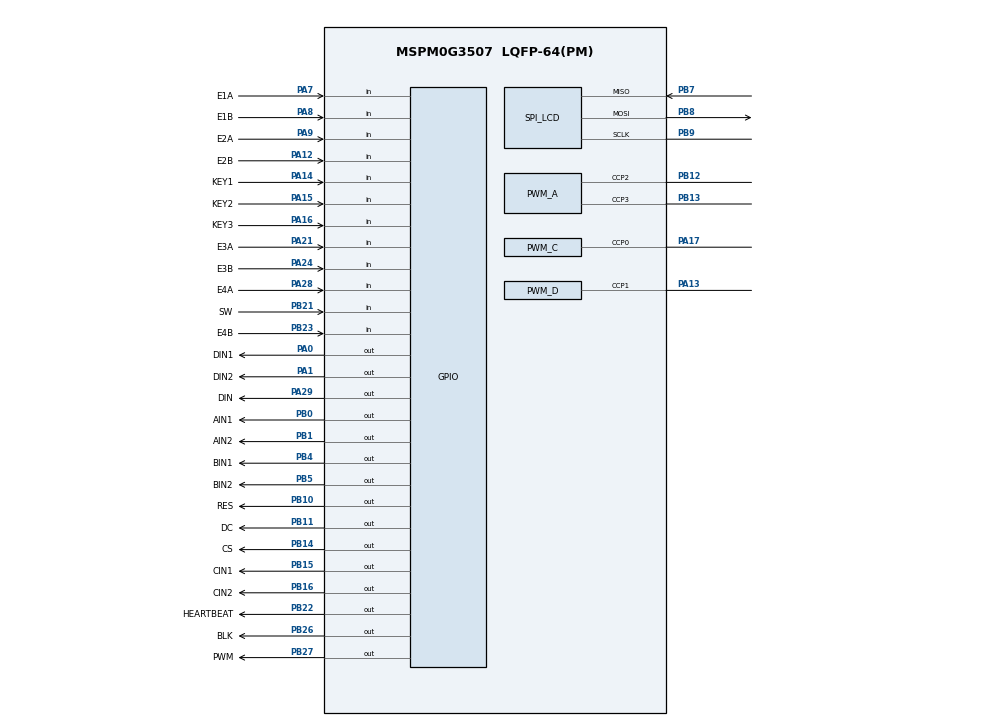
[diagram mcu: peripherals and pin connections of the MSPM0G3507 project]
/**
 * @cliArgs --device "MSPM0G3507" --package "LQFP-64(PM)" --product "mspm0_sdk@2.11.00.07"
 */
const GPIO = scripting.addModule("/ti/driverlib/GPIO", {}, false);
const LCD_RES = GPIO.addInstance();
const LCD_DC = GPIO.addInstance();
const LCD_CS = GPIO.addInstance();
const LCD_BLK = GPIO.addInstance();
const KEY_INPUT = GPIO.addInstance();
const KEY1_INPUT = GPIO.addInstance();
const KEY2_INPUT = GPIO.addInstance();
const KEY3_INPUT = GPIO.addInstance();
const DIR_A = GPIO.addInstance();
const DIR_B = GPIO.addInstance();
const DIR_C = GPIO.addInstance();
const DIR_D = GPIO.addInstance();
const ENCODER_A = GPIO.addInstance();
const ENCODER_B = GPIO.addInstance();
const ENCODER_C = GPIO.addInstance();
const ENCODER_D_A = GPIO.addInstance();
const ENCODER_D_B = GPIO.addInstance();
const GPIO_HEARTBEAT = GPIO.addInstance();
const WS2812 = GPIO.addInstance();
const BUZZER = GPIO.addInstance();
const PWM = scripting.addModule("/ti/driverlib/PWM", {}, false);
const PWM_A = PWM.addInstance();
const PWM_D = PWM.addInstance();
const SPI = scripting.addModule("/ti/driverlib/SPI", {}, false);
const SPI_LCD = SPI.addInstance();
const SYSCTL = scripting.addModule("/ti/driverlib/SYSCTL");
const Board = scripting.addModule("/ti/driverlib/Board", {}, false);

LCD_RES.$name = "LCD_RES";
LCD_RES.port = "PORTB";
LCD_RES.associatedPins[0].$name = "RES";
LCD_RES.associatedPins[0].assignedPort = "PORTB";
LCD_RES.associatedPins[0].assignedPin = "10";
LCD_RES.associatedPins[0].direction = "OUTPUT";
LCD_RES.associatedPins[0].initialValue = "SET";
LCD_RES.associatedPins[0].pin.$assign = "PB10";

LCD_DC.$name = "LCD_DC";
LCD_DC.port = "PORTB";
LCD_DC.associatedPins[0].$name = "DC";
LCD_DC.associatedPins[0].assignedPort = "PORTB";
LCD_DC.associatedPins[0].assignedPin = "11";
LCD_DC.associatedPins[0].direction = "OUTPUT";
LCD_DC.associatedPins[0].initialValue = "SET";
LCD_DC.associatedPins[0].pin.$assign = "PB11";

LCD_CS.$name = "LCD_CS";
LCD_CS.port = "PORTB";
LCD_CS.associatedPins[0].$name = "CS";
LCD_CS.associatedPins[0].assignedPort = "PORTB";
LCD_CS.associatedPins[0].assignedPin = "14";
LCD_CS.associatedPins[0].direction = "OUTPUT";
LCD_CS.associatedPins[0].initialValue = "SET";
LCD_CS.associatedPins[0].pin.$assign = "PB14";

LCD_BLK.$name = "LCD_BLK";
LCD_BLK.port = "PORTB";
LCD_BLK.associatedPins[0].$name = "BLK";
LCD_BLK.associatedPins[0].assignedPort = "PORTB";
LCD_BLK.associatedPins[0].assignedPin = "26";
LCD_BLK.associatedPins[0].direction = "OUTPUT";
LCD_BLK.associatedPins[0].initialValue = "CLEARED";
LCD_BLK.associatedPins[0].pin.$assign = "PB26";

KEY_INPUT.$name = "KEY_INPUT";
KEY_INPUT.port = "PORTB";
KEY_INPUT.associatedPins[0].$name = "SW";
KEY_INPUT.associatedPins[0].assignedPort = "PORTB";
KEY_INPUT.associatedPins[0].assignedPin = "21";
KEY_INPUT.associatedPins[0].direction = "INPUT";
KEY_INPUT.associatedPins[0].internalResistor = "PULL_UP";
KEY_INPUT.associatedPins[0].pin.$assign = "PB21";

KEY1_INPUT.$name = "KEY1_INPUT";
KEY1_INPUT.port = "PORTA";
KEY1_INPUT.associatedPins[0].$name = "KEY1";
KEY1_INPUT.associatedPins[0].assignedPort = "PORTA";
KEY1_INPUT.associatedPins[0].assignedPin = "14";
KEY1_INPUT.associatedPins[0].direction = "INPUT";
KEY1_INPUT.associatedPins[0].internalResistor = "PULL_UP";
KEY1_INPUT.associatedPins[0].pin.$assign = "PA14";

KEY2_INPUT.$name = "KEY2_INPUT";
KEY2_INPUT.port = "PORTA";
KEY2_INPUT.associatedPins[0].$name = "KEY2";
KEY2_INPUT.associatedPins[0].assignedPort = "PORTA";
KEY2_INPUT.associatedPins[0].assignedPin = "15";
KEY2_INPUT.associatedPins[0].direction = "INPUT";
KEY2_INPUT.associatedPins[0].internalResistor = "PULL_UP";
KEY2_INPUT.associatedPins[0].pin.$assign = "PA15";

KEY3_INPUT.$name = "KEY3_INPUT";
KEY3_INPUT.port = "PORTA";
KEY3_INPUT.associatedPins[0].$name = "KEY3";
KEY3_INPUT.associatedPins[0].assignedPort = "PORTA";
KEY3_INPUT.associatedPins[0].assignedPin = "16";
KEY3_INPUT.associatedPins[0].direction = "INPUT";
KEY3_INPUT.associatedPins[0].internalResistor = "PULL_UP";
KEY3_INPUT.associatedPins[0].pin.$assign = "PA16";

DIR_A.$name = "DIR_A";
DIR_A.port = "PORTB";
DIR_A.associatedPins.create(2);
DIR_A.associatedPins[0].$name = "AIN1";
DIR_A.associatedPins[0].assignedPort = "PORTB";
DIR_A.associatedPins[0].assignedPin = "0";
DIR_A.associatedPins[0].direction = "OUTPUT";
DIR_A.associatedPins[0].initialValue = "CLEARED";
DIR_A.associatedPins[0].pin.$assign = "PB0";
DIR_A.associatedPins[1].$name = "AIN2";
DIR_A.associatedPins[1].assignedPort = "PORTB";
DIR_A.associatedPins[1].assignedPin = "1";
DIR_A.associatedPins[1].direction = "OUTPUT";
DIR_A.associatedPins[1].initialValue = "CLEARED";
DIR_A.associatedPins[1].pin.$assign = "PB1";

DIR_B.$name = "DIR_B";
DIR_B.port = "PORTB";
DIR_B.associatedPins.create(2);
DIR_B.associatedPins[0].$name = "BIN1";
DIR_B.associatedPins[0].assignedPort = "PORTB";
DIR_B.associatedPins[0].assignedPin = "4";
DIR_B.associatedPins[0].direction = "OUTPUT";
DIR_B.associatedPins[0].initialValue = "CLEARED";
DIR_B.associatedPins[0].pin.$assign = "PB4";
DIR_B.associatedPins[1].$name = "BIN2";
DIR_B.associatedPins[1].assignedPort = "PORTB";
DIR_B.associatedPins[1].assignedPin = "5";
DIR_B.associatedPins[1].direction = "OUTPUT";
DIR_B.associatedPins[1].initialValue = "CLEARED";
DIR_B.associatedPins[1].pin.$assign = "PB5";

DIR_C.$name = "DIR_C";
DIR_C.port = "PORTB";
DIR_C.associatedPins.create(2);
DIR_C.associatedPins[0].$name = "CIN1";
DIR_C.associatedPins[0].assignedPort = "PORTB";
DIR_C.associatedPins[0].assignedPin = "15";
DIR_C.associatedPins[0].direction = "OUTPUT";
DIR_C.associatedPins[0].initialValue = "CLEARED";
DIR_C.associatedPins[0].pin.$assign = "PB15";
DIR_C.associatedPins[1].$name = "CIN2";
DIR_C.associatedPins[1].assignedPort = "PORTB";
DIR_C.associatedPins[1].assignedPin = "16";
DIR_C.associatedPins[1].direction = "OUTPUT";
DIR_C.associatedPins[1].initialValue = "CLEARED";
DIR_C.associatedPins[1].pin.$assign = "PB16";

DIR_D.$name = "DIR_D";
DIR_D.port = "PORTA";
DIR_D.associatedPins.create(2);
DIR_D.associatedPins[0].$name = "DIN1";
DIR_D.associatedPins[0].assignedPort = "PORTA";
DIR_D.associatedPins[0].assignedPin = "0";
DIR_D.associatedPins[0].direction = "OUTPUT";
DIR_D.associatedPins[0].initialValue = "CLEARED";
DIR_D.associatedPins[0].pin.$assign = "PA0";
DIR_D.associatedPins[1].$name = "DIN2";
DIR_D.associatedPins[1].assignedPort = "PORTA";
DIR_D.associatedPins[1].assignedPin = "1";
DIR_D.associatedPins[1].direction = "OUTPUT";
DIR_D.associatedPins[1].initialValue = "CLEARED";
DIR_D.associatedPins[1].pin.$assign = "PA1";

ENCODER_A.$name = "ENCODER_A";
ENCODER_A.port = "PORTA";
ENCODER_A.associatedPins.create(2);
ENCODER_A.associatedPins[0].$name = "E1A";
ENCODER_A.associatedPins[0].assignedPort = "PORTA";
ENCODER_A.associatedPins[0].assignedPin = "7";
ENCODER_A.associatedPins[0].direction = "INPUT";
ENCODER_A.associatedPins[0].internalResistor = "PULL_UP";
ENCODER_A.associatedPins[0].pin.$assign = "PA7";
ENCODER_A.associatedPins[1].$name = "E1B";
ENCODER_A.associatedPins[1].assignedPort = "PORTA";
ENCODER_A.associatedPins[1].assignedPin = "8";
ENCODER_A.associatedPins[1].direction = "INPUT";
ENCODER_A.associatedPins[1].internalResistor = "PULL_UP";
ENCODER_A.associatedPins[1].pin.$assign = "PA8";

ENCODER_B.$name = "ENCODER_B";
ENCODER_B.port = "PORTA";
ENCODER_B.associatedPins.create(2);
ENCODER_B.associatedPins[0].$name = "E2A";
ENCODER_B.associatedPins[0].assignedPort = "PORTA";
ENCODER_B.associatedPins[0].assignedPin = "9";
ENCODER_B.associatedPins[0].direction = "INPUT";
ENCODER_B.associatedPins[0].internalResistor = "PULL_UP";
ENCODER_B.associatedPins[0].pin.$assign = "PA9";
ENCODER_B.associatedPins[1].$name = "E2B";
ENCODER_B.associatedPins[1].assignedPort = "PORTA";
ENCODER_B.associatedPins[1].assignedPin = "12";
ENCODER_B.associatedPins[1].direction = "INPUT";
ENCODER_B.associatedPins[1].internalResistor = "PULL_UP";
ENCODER_B.associatedPins[1].pin.$assign = "PA12";

ENCODER_C.$name = "ENCODER_C";
ENCODER_C.port = "PORTA";
ENCODER_C.associatedPins.create(2);
ENCODER_C.associatedPins[0].$name = "E3A";
ENCODER_C.associatedPins[0].assignedPort = "PORTA";
ENCODER_C.associatedPins[0].assignedPin = "21";
ENCODER_C.associatedPins[0].direction = "INPUT";
ENCODER_C.associatedPins[0].internalResistor = "PULL_UP";
ENCODER_C.associatedPins[0].pin.$assign = "PA21";
ENCODER_C.associatedPins[1].$name = "E3B";
ENCODER_C.associatedPins[1].assignedPort = "PORTA";
ENCODER_C.associatedPins[1].assignedPin = "24";
ENCODER_C.associatedPins[1].direction = "INPUT";
ENCODER_C.associatedPins[1].internalResistor = "PULL_UP";
ENCODER_C.associatedPins[1].pin.$assign = "PA24";

ENCODER_D_A.$name = "ENCODER_D_A";
ENCODER_D_A.port = "PORTA";
ENCODER_D_A.associatedPins[0].$name = "E4A";
ENCODER_D_A.associatedPins[0].assignedPort = "PORTA";
ENCODER_D_A.associatedPins[0].assignedPin = "28";
ENCODER_D_A.associatedPins[0].direction = "INPUT";
ENCODER_D_A.associatedPins[0].internalResistor = "PULL_UP";
ENCODER_D_A.associatedPins[0].pin.$assign = "PA28";

ENCODER_D_B.$name = "ENCODER_D_B";
ENCODER_D_B.port = "PORTB";
ENCODER_D_B.associatedPins[0].$name = "E4B";
ENCODER_D_B.associatedPins[0].assignedPort = "PORTB";
ENCODER_D_B.associatedPins[0].assignedPin = "23";
ENCODER_D_B.associatedPins[0].direction = "INPUT";
ENCODER_D_B.associatedPins[0].internalResistor = "PULL_UP";
ENCODER_D_B.associatedPins[0].pin.$assign = "PB23";

GPIO_HEARTBEAT.$name = "GPIO_HEARTBEAT";
GPIO_HEARTBEAT.port = "PORTB";
GPIO_HEARTBEAT.associatedPins[0].$name = "HEARTBEAT";
GPIO_HEARTBEAT.associatedPins[0].assignedPort = "PORTB";
GPIO_HEARTBEAT.associatedPins[0].assignedPin = "22";
GPIO_HEARTBEAT.associatedPins[0].direction = "OUTPUT";
GPIO_HEARTBEAT.associatedPins[0].initialValue = "CLEARED";
GPIO_HEARTBEAT.associatedPins[0].pin.$assign = "PB22";

WS2812.$name = "WS2812";
WS2812.port = "PORTA";
WS2812.associatedPins[0].$name = "DIN";
WS2812.associatedPins[0].assignedPort = "PORTA";
WS2812.associatedPins[0].assignedPin = "29";
WS2812.associatedPins[0].direction = "OUTPUT";
WS2812.associatedPins[0].initialValue = "CLEARED";
WS2812.associatedPins[0].pin.$assign = "PA29";
// bsp_ws2812.c temporarily remuxes PA29 to TIMG6_CCP0 and reserves DMA_CH0.

BUZZER.$name = "BUZZER";
BUZZER.port = "PORTB";
BUZZER.associatedPins[0].$name = "PWM";
BUZZER.associatedPins[0].assignedPort = "PORTB";
BUZZER.associatedPins[0].assignedPin = "27";
BUZZER.associatedPins[0].direction = "OUTPUT";
BUZZER.associatedPins[0].initialValue = "CLEARED";
BUZZER.associatedPins[0].pin.$assign = "PB27";

PWM_A.$name = "PWM_A";
PWM_A.clockDivider = 2;
PWM_A.timerCount = 800;
PWM_A.ccIndex = [2,3];
PWM_A.PWM_CHANNEL_2.$name = "ti_driverlib_pwm_PWMTimerCC2";
PWM_A.PWM_CHANNEL_3.$name = "ti_driverlib_pwm_PWMTimerCC3";
PWM_A.ccp2PinConfig.$name = "PWM_A_PIN";
PWM_A.ccp3PinConfig.$name = "PWM_B_PIN";
PWM_A.peripheral.$assign = "TIMA0";
PWM_A.peripheral.ccp2Pin.$assign = "PB12";
PWM_A.peripheral.ccp3Pin.$assign = "PB13";

const PWM_C = PWM.addInstance();
PWM_C.$name = "PWM_C";
PWM_C.clockDivider = 2;
PWM_C.timerCount = 800;
PWM_C.ccIndex = [0];
PWM_C.PWM_CHANNEL_0.$name = "ti_driverlib_pwm_PWMTimerCC0";
PWM_C.ccp0PinConfig.$name = "PWM_C_PIN";
PWM_C.peripheral.$assign = "TIMA1";
PWM_C.peripheral.ccp0Pin.$assign = "PA17";

PWM_D.$name = "PWM_D";
PWM_D.clockDivider = 2;
PWM_D.timerCount = 800;
PWM_D.ccIndex = [1];
PWM_D.PWM_CHANNEL_1.$name = "ti_driverlib_pwm_PWMTimerCC1";
PWM_D.ccp1PinConfig.$name = "PWM_D_PIN";
PWM_D.peripheral.$assign = "TIMG0";
PWM_D.peripheral.ccp1Pin.$assign = "PA13";

SPI_LCD.$name = "SPI_LCD";
SPI_LCD.targetBitRate = 8000000;
SPI_LCD.frameFormat = "MOTO3";
SPI_LCD.peripheral.sclkPin.$assign = "PB9";
SPI_LCD.peripheral.mosiPin.$assign = "PB8";
SPI_LCD.peripheral.misoPin.$assign = "PB7";
SPI_LCD.sclkPinConfig.$name = "SPI_LCD_SCLK";
SPI_LCD.sclkPinConfig.direction = scripting.forceWrite("OUTPUT");
SPI_LCD.sclkPinConfig.onlyInternalResistor = scripting.forceWrite(false);
SPI_LCD.sclkPinConfig.passedPeripheralType = scripting.forceWrite("Digital");
SPI_LCD.mosiPinConfig.$name = "SPI_LCD_MOSI";
SPI_LCD.mosiPinConfig.direction = scripting.forceWrite("OUTPUT");
SPI_LCD.mosiPinConfig.hideOutputInversion = scripting.forceWrite(false);
SPI_LCD.mosiPinConfig.onlyInternalResistor = scripting.forceWrite(false);
SPI_LCD.mosiPinConfig.passedPeripheralType = scripting.forceWrite("Digital");
SPI_LCD.misoPinConfig.$name = "SPI_LCD_MISO_UNUSED";
SPI_LCD.misoPinConfig.onlyInternalResistor = scripting.forceWrite(false);
SPI_LCD.misoPinConfig.passedPeripheralType = scripting.forceWrite("Digital");

SYSCTL.clockTreeEn = true;
Board.peripheral.$suggestSolution = "DEBUGSS";
Board.peripheral.swclkPin.$suggestSolution = "PA20";
Board.peripheral.swdioPin.$suggestSolution = "PA19";
SPI_LCD.peripheral.$suggestSolution = "SPI1";
PWM_A.peripheral.$suggestSolution = "TIMA0";
PWM_C.peripheral.$suggestSolution = "TIMA1";
PWM_D.peripheral.$suggestSolution = "TIMG0";
